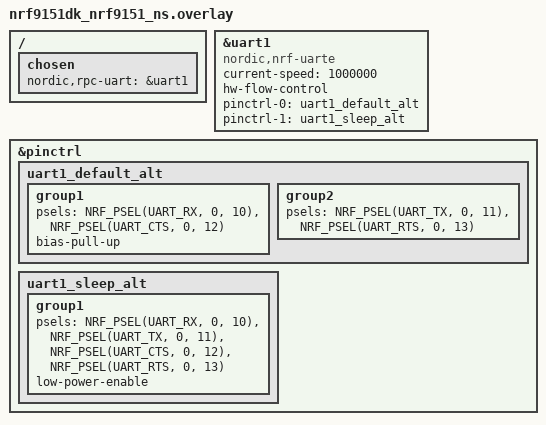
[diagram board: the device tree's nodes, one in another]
/*
 * Copyright (c) 2026 Nordic Semiconductor ASA
 *
 * SPDX-License-Identifier: LicenseRef-Nordic-5-Clause
 *
 * RPC over UART1.
 *
 * Pins: RX P0.10, TX P0.11, CTS P0.12, RTS P0.13 (cross TX-RX and RTS-CTS to peer).
 *
 * Flash layout without MCUboot (960 kB non-secure app region); required with
 * PARTITION_MANAGER=n because the default nrf91xx slot0_ns is only 192 kB.
 */

#include <samples/cellular/nrf91_no_bootloader_partitions.dtsi>

/ {
	chosen {
		nordic,rpc-uart = &uart1;
	};
};

&uart1 {
	compatible = "nordic,nrf-uarte";
	status = "okay";
	current-speed = <1000000>;
	hw-flow-control;

	pinctrl-0 = <&uart1_default_alt>;
	pinctrl-1 = <&uart1_sleep_alt>;
	pinctrl-names = "default", "sleep";
};

&pinctrl {
	uart1_default_alt: uart1_default_alt {
		group1 {
			psels = <NRF_PSEL(UART_RX, 0, 10)>,
				<NRF_PSEL(UART_CTS, 0, 12)>;
			bias-pull-up;
		};

		group2 {
			psels = <NRF_PSEL(UART_TX, 0, 11)>,
				<NRF_PSEL(UART_RTS, 0, 13)>;
		};
	};

	uart1_sleep_alt: uart1_sleep_alt {
		group1 {
			psels = <NRF_PSEL(UART_RX, 0, 10)>,
				<NRF_PSEL(UART_TX, 0, 11)>,
				<NRF_PSEL(UART_CTS, 0, 12)>,
				<NRF_PSEL(UART_RTS, 0, 13)>;
			low-power-enable;
		};
	};
};
